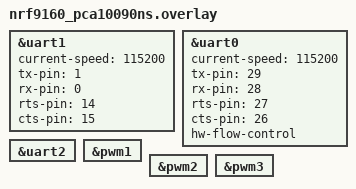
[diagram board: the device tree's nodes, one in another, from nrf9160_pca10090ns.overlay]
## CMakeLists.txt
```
#
# Copyright (c) 2018 Nordic Semiconductor ASA
#
# SPDX-License-Identifier: LicenseRef-Nordic-5-Clause
#

cmake_minimum_required(VERSION 3.20.1)

find_package(Zephyr REQUIRED HINTS $ENV{ZEPHYR_BASE})
project(aqs-gateway)

# NORDIC SDK APP START
target_sources(app PRIVATE src/main.c)
# NORDIC SDK APP END
```

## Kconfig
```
#
# Copyright (c) 2020 Nordic Semiconductor ASA
#
# SPDX-License-Identifier: LicenseRef-Nordic-5-Clause
#

menu "MQTT simple sample"
config MQTT_PUB_TOPIC
	string "MQTT publish topic"
	default "/my/publish/topic"

config MQTT_SUB_TOPIC
	string "MQTT subscribe topic"
	default "/my/subscribe/topic"

config MQTT_CLIENT_ID
	string "MQTT Client ID"
	help
	  Use a custom Client ID string. If not set, the client ID will be
	  generated based on IMEI number (for nRF9160 based targets) or
	  randomly (for other platforms).
	default ""

config MQTT_BROKER_HOSTNAME
	string "MQTT broker hostname"
	default "mqtt.eclipse.org"

config MQTT_BROKER_PORT
	int "MQTT broker port"
	default 1883

config MQTT_MESSAGE_BUFFER_SIZE
	int "MQTT message buffer size"
	default 512

config MQTT_PAYLOAD_BUFFER_SIZE
	int "MQTT payload buffer size"
	default 512

config BUTTON_EVENT_PUBLISH_MSG
	string "The message to publish on a button event"
	default "Hello from nRF91 MQTT Simple Sample"

config BUTTON_EVENT_BTN_NUM
	int "The button number"
	default 1

config MQTT_RECONNECT_DELAY_S
	int "Seconds to delay before attempting to reconnect to the broker."
	default 60

config LTE_CONNECT_RETRY_DELAY_S
	int "Seconds to delay before attempting to retry LTE connection."
	default 120

config MQTT_TLS_SEC_TAG
	int "TLS credentials security tag"
	default 24
	# default 100 (from custom version)

config MQTT_TLS_SESSION_CACHING
	bool "Enable TLS session caching"

config MQTT_TLS_PEER_VERIFY
	int "Set peer verification level"
	default 2
	# default 1 (from custom version)
	help
		Set to 0 for VERIFY_NONE, 1 for VERIFY_OPTIONAL, and 2 for
		VERIFY_REQUIRED.

endmenu

menu "Zephyr Kernel"
source "Kconfig.zephyr"
endmenu

module = MQTT_SIMPLE
module-str = MQTT Simple
source "${ZEPHYR_BASE}/subsys/logging/Kconfig.template.log_config"
```

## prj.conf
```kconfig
#
# Copyright (c) 2020 Nordic Semiconductor ASA
#
# SPDX-License-Identifier: LicenseRef-Nordic-5-Clause
#

# Networking
CONFIG_NETWORKING=y
CONFIG_NET_NATIVE=n
CONFIG_NET_SOCKETS_OFFLOAD=y
CONFIG_NET_SOCKETS=y
CONFIG_NET_SOCKETS_POSIX_NAMES=y

# LTE link control
CONFIG_LTE_NETWORK_USE_FALLBACK=n
CONFIG_LTE_LINK_CONTROL=y
CONFIG_LTE_AUTO_INIT_AND_CONNECT=n

# CONFIG_LTE_LOCK_BANDS=y
# CONFIG_LTE_LOCK_BAND_MASK="00010001100001001000"

# Modem library
CONFIG_NRF_MODEM_LIB=y

# AT Host
CONFIG_UART_INTERRUPT_DRIVEN=y
CONFIG_AT_HOST_LIBRARY=y

# MQTT
CONFIG_MQTT_LIB=y
CONFIG_MQTT_LIB_TLS=n
CONFIG_MQTT_CLEAN_SESSION=y

# IoT Hub Settings
CONFIG_MQTT_PUB_TOPIC="devices/aqsdevice27/messages/events/"
CONFIG_MQTT_SUB_TOPIC="devices/aqsdevice27messages/devicebound/"
CONFIG_MQTT_CLIENT_ID="aqsdevice22"

CONFIG_MQTT_BROKER_HOSTNAME="AquaHub2.azure-devices.net"
CONFIG_MQTT_BROKER_PORT=8883
CONFIG_MQTT_KEEPALIVE=900

# Application - Misc
CONFIG_REBOOT=y
CONFIG_SERIAL=y
CONFIG_GPIO=y
# CONFIG_UART_1_NRF_UARTE=y

# Button support
# CONFIG_DK_LIBRARY=y

# Enable logging
CONFIG_LOG=y
CONFIG_MQTT_SIMPLE_LOG_LEVEL_DBG=y
# CONFIG_LTE_LINK_CONTROL_LOG_LEVEL_DBG=y

# Memory
CONFIG_MAIN_STACK_SIZE=8192
CONFIG_HEAP_MEM_POOL_SIZE=4096
# CONFIG_SYSTEM_WORKQUEUE_STACK_SIZE=1024

# NewLib C
CONFIG_NEWLIB_LIBC=y
```

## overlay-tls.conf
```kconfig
#
# Copyright (c) 2020 Nordic Semiconductor ASA
#
# SPDX-License-Identifier: LicenseRef-Nordic-5-Clause
#

# MQTT TLS
CONFIG_MQTT_LIB_TLS=y
CONFIG_MQTT_BROKER_PORT=8883

# Application - TLS
CONFIG_MQTT_TLS_SEC_TAG=100
CONFIG_MQTT_TLS_PEER_VERIFY=1

# Modem key management, for provisioning certificates
CONFIG_MODEM_KEY_MGMT=y
```

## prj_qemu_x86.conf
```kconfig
#
# Copyright (c) 2019 Nordic Semiconductor ASA
#
# SPDX-License-Identifier: LicenseRef-BSD-5-Clause-Nordic
#
# General config
CONFIG_TEST_RANDOM_GENERATOR=y
CONFIG_NEWLIB_LIBC=y

# MQTT
CONFIG_MQTT_LIB=y
CONFIG_MQTT_LIB_TLS=y

# Networking config
CONFIG_NETWORKING=y
CONFIG_NET_IPV4=y
CONFIG_NET_TCP=y
CONFIG_NET_SOCKETS=y
CONFIG_NET_SOCKETS_POSIX_NAMES=y

CONFIG_DNS_RESOLVER=y
CONFIG_DNS_SERVER_IP_ADDRESSES=y
CONFIG_DNS_SERVER1="8.8.8.8"

# Network address config
CONFIG_NET_CONFIG_SETTINGS=y
CONFIG_NET_CONFIG_NEED_IPV4=y
CONFIG_NET_CONFIG_MY_IPV4_ADDR="192.0.2.1"
CONFIG_NET_CONFIG_PEER_IPV4_ADDR="192.0.2.2"
CONFIG_NET_CONFIG_MY_IPV4_GW="192.0.2.2"

# Appliaction
#CONFIG_MQTT_PUB_TOPIC="/my/publish/topic"
#CONFIG_MQTT_SUB_TOPIC="/my/subscribe/topic"
#CONFIG_MQTT_CLIENT_ID="my-client-id"
#CONFIG_MQTT_BROKER_HOSTNAME="mqtt.eclipse.org"
#CONFIG_MQTT_BROKER_PORT=1883

# Main thread
CONFIG_HEAP_MEM_POOL_SIZE=16384
CONFIG_MAIN_STACK_SIZE=16384
```

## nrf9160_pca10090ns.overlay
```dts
/* Needed to get NRF_UARTE2 and NRF_PWMn defined. */
//For BLG840,PCA10090,SE9160-210
&uart1 {
  current-speed = <115200>;
  status = "ok";
  tx-pin = <1>;
  rx-pin = <0>;
  rts-pin = <14>;
  cts-pin = <15>;
};

&uart0 {
  current-speed = <115200>;
  status = "ok";
  tx-pin = <29>;
  rx-pin = <28>;
  rts-pin = <27>;
  cts-pin = <26>;
  hw-flow-control;
};
//For BLE60E40F
/*
&uart0 {
  current-speed = <115200>;
  status = "ok";
  tx-pin = <1>;
  rx-pin = <0>;
  rts-pin = <14>;
  cts-pin = <15>;
};

&uart1 {
  current-speed = <115200>;
  status = "ok";
  tx-pin = <29>;
  rx-pin = <28>;
  rts-pin = <27>;
  cts-pin = <26>;
};
*/
&uart2 {
	status = "ok";
};

&pwm1 {
	status = "ok";
};

&pwm2 {
	status = "ok";
};

&pwm3 {
	status = "ok";
};
```

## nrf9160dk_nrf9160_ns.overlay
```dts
//For BLG840F
&uart0 {
  current-speed = <115200>;
  status = "ok";
  tx-pin = <29>;
  rx-pin = <28>;
  rts-pin = <27>;
  cts-pin = <26>;
  hw-flow-control; // disable if debugging on the 9160 DK
};

&pwm1 {
	status = "ok";
};

&pwm2 {
	status = "ok";
};

&pwm3 {
	status = "ok";
};
```

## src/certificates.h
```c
/*
 * Copyright (c) 2020 Nordic Semiconductor ASA
 *
 * SPDX-License-Identifier: LicenseRef-Nordic-5-Clause
 */

// Copyright (c) Microsoft. All rights reserved.
// Licensed under the MIT license. See LICENSE file in the project root for full license information.

/* This file contains certs needed to communicate with Azure (IoT) */

//#include "certs.h"
/* Note: for devices with limited resources, only one cert should be loaded. 
   #defines are used to reduce memory footprint of certificates.
   For DE and CN regions, please build with -DUSE_MICROSOFTAZURE_DE_CERT or -DUSE_PORTAL_AZURE_CN_CERT, respectively, 
   if you wish to load ONLY those certs.
*/
// #if !defined(USE_BALTIMORE_CERT) && !defined(USE_MICROSOFTAZURE_DE_CERT) && !defined(USE_PORTAL_AZURE_CN_CERT)
// // For legacy, if no certificates were explicitly selected then include all of them
// #define USE_BALTIMORE_CERT
// #define USE_MICROSOFTAZURE_DE_CERT 
// #define USE_PORTAL_AZURE_CN_CERT
// #endif
//#ifndef USE_BALTIMORE_CERT  
//#define USE_BALTIMORE_CERT
//#endif

//const char certificates[] =
///* DigiCert Baltimore Root --Used Globally--*/
//// This cert should be used when connecting to Azure IoT on the Azure Cloud available globally. When in doubt, use this cert.
//"-----BEGIN CERTIFICATE-----MIIDdzCCAl+gAwIBAgIEAgAAuTANBgkqhkiG9w0BAQUFADBaMQswCQYDVQQGEwJJRTESMBAGA1UEChMJQmFsdGltb3JlMRMwEQYDVQQLEwpDeWJlclRydXN0MSIwIAYDVQQDExlCYWx0aW1vcmUgQ3liZXJUcnVzdCBSb290MB4XDTAwMDUxMjE4NDYwMFoXDTI1MDUxMjIzNTkwMFowWjELMAkGA1UEBhMCSUUxEjAQBgNVBAoTCUJhbHRpbW9yZTETMBEGA1UECxMKQ3liZXJUcnVzdDEiMCAGA1UEAxMZQmFsdGltb3JlIEN5YmVyVHJ1c3QgUm9vdDCCASIwDQYJKoZIhvcNAQEBBQADggEPADCCAQoCggEBAKMEuyKrmD1X6CZymrV51Cni4eiVgLGw41uOKymaZN+hXe2wCQVt2yguzmKiYv60iNoS6zjrIZ3AQSsBUnuId9Mcj8e6uYi1agnnc+gRQKfRzMpijS3ljwumUNKoUMMo6vWrJYeKmpYcqWe4PwzV9/lSEy/CG9VwcPCPwBLKBsua4dnKM3p31vjsufFoREJIE9LAwqSuXmD+tqYF/LTdB1kC1FkYmGP1pWPgkAx9XbIGevOF6uvUA65ehD5f/xXtabz5OTZydc93Uk3zyZAsuT3lySNTPx8kmCFcB5kpvcY67Oduhjprl3RjM71oGDHweI12v/yejl0qhqdNkNwnGjkCAwEAAaNFMEMwHQYDVR0OBBYEFOWdWTCCR1jMrPoIVDaGezq1BE3wMBIGA1UdEwEB/wQIMAYBAf8CAQMwDgYDVR0PAQH/BAQDAgEGMA0GCSqGSIb3DQEBBQUAA4IBAQCFDF2O5G9RaEIFoN27TyclhAO992T9Ldcw46QQF+vaKSm2eT929hkTI7gQCvlYpNRhcL0EYWoSihfVCr3FvDB81ukMJY2GQE/szKN+OMY3EU/t3WgxjkzSswF07r51XgdIGn9w/xZchMB5hbgF/X++ZRGjD8ACtPhSNzkE1akxehi/oCr0Epn3o0WC4zxe9Z2etciefC7IpJ5OCBRLbf1wbWsaY71k5h+3zvDyny67G7fyUIhzksLi4xaNmjICq44Y3ekQEe5+NauQrz4wlHrQMz2nZQ/1/I6eYs9HRCwBXbsdtTLSR9I4LtD+gdwyah617jzV/OeBHRnDJELqYzmp-----END CERTIFICATE-----"
//;

#define CA_CERTIFICATE \
	"-----BEGIN CERTIFICATE-----\n" \
	"MIIDdzCCAl+gAwIBAgIEAgAAuTANBgkqhkiG9w0BAQUFADBaMQswCQYDVQQGEwJJ\n" \
	"RTESMBAGA1UEChMJQmFsdGltb3JlMRMwEQYDVQQLEwpDeWJlclRydXN0MSIwIAYD\n" \
	"VQQDExlCYWx0aW1vcmUgQ3liZXJUcnVzdCBSb290MB4XDTAwMDUxMjE4NDYwMFoX\n" \
	"DTI1MDUxMjIzNTkwMFowWjELMAkGA1UEBhMCSUUxEjAQBgNVBAoTCUJhbHRpbW9y\n" \
	"ZTETMBEGA1UECxMKQ3liZXJUcnVzdDEiMCAGA1UEAxMZQmFsdGltb3JlIEN5YmVy\n" \
	"VHJ1c3QgUm9vdDCCASIwDQYJKoZIhvcNAQEBBQADggEPADCCAQoCggEBAKMEuyKr\n" \
	"mD1X6CZymrV51Cni4eiVgLGw41uOKymaZN+hXe2wCQVt2yguzmKiYv60iNoS6zjr\n" \
	"IZ3AQSsBUnuId9Mcj8e6uYi1agnnc+gRQKfRzMpijS3ljwumUNKoUMMo6vWrJYeK\n" \
	"mpYcqWe4PwzV9/lSEy/CG9VwcPCPwBLKBsua4dnKM3p31vjsufFoREJIE9LAwqSu\n" \
	"XmD+tqYF/LTdB1kC1FkYmGP1pWPgkAx9XbIGevOF6uvUA65ehD5f/xXtabz5OTZy\n" \
	"dc93Uk3zyZAsuT3lySNTPx8kmCFcB5kpvcY67Oduhjprl3RjM71oGDHweI12v/ye\n" \
	"jl0qhqdNkNwnGjkCAwEAAaNFMEMwHQYDVR0OBBYEFOWdWTCCR1jMrPoIVDaGezq1\n" \
	"BE3wMBIGA1UdEwEB/wQIMAYBAf8CAQMwDgYDVR0PAQH/BAQDAgEGMA0GCSqGSIb3\n" \
	"DQEBBQUAA4IBAQCFDF2O5G9RaEIFoN27TyclhAO992T9Ldcw46QQF+vaKSm2eT92\n" \
	"9hkTI7gQCvlYpNRhcL0EYWoSihfVCr3FvDB81ukMJY2GQE/szKN+OMY3EU/t3Wgx\n" \
	"jkzSswF07r51XgdIGn9w/xZchMB5hbgF/X++ZRGjD8ACtPhSNzkE1akxehi/oCr0\n" \
	"Epn3o0WC4zxe9Z2etciefC7IpJ5OCBRLbf1wbWsaY71k5h+3zvDyny67G7fyUIhz\n" \
	"ksLi4xaNmjICq44Y3ekQEe5+NauQrz4wlHrQMz2nZQ/1/I6eYs9HRCwBXbsdtTLS\n" \
	"R9I4LtD+gdwyah617jzV/OeBHRnDJELqYzmp\n" \
	"-----END CERTIFICATE-----\n"
```

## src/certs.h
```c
// Copyright (c) Microsoft. All rights reserved.
// Licensed under the MIT license. See LICENSE file in the project root for full license information.

/* This file contains certs needed to communicate with Azure (IoT) */

//#include "certs.h"
/* Note: for devices with limited resources, only one cert should be loaded. 
   #defines are used to reduce memory footprint of certificates.
   For DE and CN regions, please build with -DUSE_MICROSOFTAZURE_DE_CERT or -DUSE_PORTAL_AZURE_CN_CERT, respectively, 
   if you wish to load ONLY those certs.
*/
// #if !defined(USE_BALTIMORE_CERT) && !defined(USE_MICROSOFTAZURE_DE_CERT) && !defined(USE_PORTAL_AZURE_CN_CERT)
// // For legacy, if no certificates were explicitly selected then include all of them
// #define USE_BALTIMORE_CERT
// #define USE_MICROSOFTAZURE_DE_CERT 
// #define USE_PORTAL_AZURE_CN_CERT
// #endif
//#ifndef USE_BALTIMORE_CERT  
//#define USE_BALTIMORE_CERT
//#endif

//const char certificates[] =
///* DigiCert Baltimore Root --Used Globally--*/
//// This cert should be used when connecting to Azure IoT on the Azure Cloud available globally. When in doubt, use this cert.
//"-----BEGIN CERTIFICATE-----MIIDdzCCAl+gAwIBAgIEAgAAuTANBgkqhkiG9w0BAQUFADBaMQswCQYDVQQGEwJJRTESMBAGA1UEChMJQmFsdGltb3JlMRMwEQYDVQQLEwpDeWJlclRydXN0MSIwIAYDVQQDExlCYWx0aW1vcmUgQ3liZXJUcnVzdCBSb290MB4XDTAwMDUxMjE4NDYwMFoXDTI1MDUxMjIzNTkwMFowWjELMAkGA1UEBhMCSUUxEjAQBgNVBAoTCUJhbHRpbW9yZTETMBEGA1UECxMKQ3liZXJUcnVzdDEiMCAGA1UEAxMZQmFsdGltb3JlIEN5YmVyVHJ1c3QgUm9vdDCCASIwDQYJKoZIhvcNAQEBBQADggEPADCCAQoCggEBAKMEuyKrmD1X6CZymrV51Cni4eiVgLGw41uOKymaZN+hXe2wCQVt2yguzmKiYv60iNoS6zjrIZ3AQSsBUnuId9Mcj8e6uYi1agnnc+gRQKfRzMpijS3ljwumUNKoUMMo6vWrJYeKmpYcqWe4PwzV9/lSEy/CG9VwcPCPwBLKBsua4dnKM3p31vjsufFoREJIE9LAwqSuXmD+tqYF/LTdB1kC1FkYmGP1pWPgkAx9XbIGevOF6uvUA65ehD5f/xXtabz5OTZydc93Uk3zyZAsuT3lySNTPx8kmCFcB5kpvcY67Oduhjprl3RjM71oGDHweI12v/yejl0qhqdNkNwnGjkCAwEAAaNFMEMwHQYDVR0OBBYEFOWdWTCCR1jMrPoIVDaGezq1BE3wMBIGA1UdEwEB/wQIMAYBAf8CAQMwDgYDVR0PAQH/BAQDAgEGMA0GCSqGSIb3DQEBBQUAA4IBAQCFDF2O5G9RaEIFoN27TyclhAO992T9Ldcw46QQF+vaKSm2eT929hkTI7gQCvlYpNRhcL0EYWoSihfVCr3FvDB81ukMJY2GQE/szKN+OMY3EU/t3WgxjkzSswF07r51XgdIGn9w/xZchMB5hbgF/X++ZRGjD8ACtPhSNzkE1akxehi/oCr0Epn3o0WC4zxe9Z2etciefC7IpJ5OCBRLbf1wbWsaY71k5h+3zvDyny67G7fyUIhzksLi4xaNmjICq44Y3ekQEe5+NauQrz4wlHrQMz2nZQ/1/I6eYs9HRCwBXbsdtTLSR9I4LtD+gdwyah617jzV/OeBHRnDJELqYzmp-----END CERTIFICATE-----"
//;


const char* certificates = {
"-----BEGIN CERTIFICATE-----\r\n"
"MIIDdzCCAl+gAwIBAgIEAgAAuTANBgkqhkiG9w0BAQUFADBaMQswCQYDVQQGEwJJ\r\n"
"RTESMBAGA1UEChMJQmFsdGltb3JlMRMwEQYDVQQLEwpDeWJlclRydXN0MSIwIAYD\r\n"
"VQQDExlCYWx0aW1vcmUgQ3liZXJUcnVzdCBSb290MB4XDTAwMDUxMjE4NDYwMFoX\r\n"
"DTI1MDUxMjIzNTkwMFowWjELMAkGA1UEBhMCSUUxEjAQBgNVBAoTCUJhbHRpbW9y\r\n"
"ZTETMBEGA1UECxMKQ3liZXJUcnVzdDEiMCAGA1UEAxMZQmFsdGltb3JlIEN5YmVy\r\n"
"VHJ1c3QgUm9vdDCCASIwDQYJKoZIhvcNAQEBBQADggEPADCCAQoCggEBAKMEuyKr\r\n"
"mD1X6CZymrV51Cni4eiVgLGw41uOKymaZN+hXe2wCQVt2yguzmKiYv60iNoS6zjr\r\n"
"IZ3AQSsBUnuId9Mcj8e6uYi1agnnc+gRQKfRzMpijS3ljwumUNKoUMMo6vWrJYeK\r\n"
"mpYcqWe4PwzV9/lSEy/CG9VwcPCPwBLKBsua4dnKM3p31vjsufFoREJIE9LAwqSu\r\n"
"XmD+tqYF/LTdB1kC1FkYmGP1pWPgkAx9XbIGevOF6uvUA65ehD5f/xXtabz5OTZy\r\n"
"dc93Uk3zyZAsuT3lySNTPx8kmCFcB5kpvcY67Oduhjprl3RjM71oGDHweI12v/ye\r\n"
"jl0qhqdNkNwnGjkCAwEAAaNFMEMwHQYDVR0OBBYEFOWdWTCCR1jMrPoIVDaGezq1\r\n"
"BE3wMBIGA1UdEwEB/wQIMAYBAf8CAQMwDgYDVR0PAQH/BAQDAgEGMA0GCSqGSIb3\r\n"
"DQEBBQUAA4IBAQCFDF2O5G9RaEIFoN27TyclhAO992T9Ldcw46QQF+vaKSm2eT92\r\n"
"9hkTI7gQCvlYpNRhcL0EYWoSihfVCr3FvDB81ukMJY2GQE/szKN+OMY3EU/t3Wgx\r\n"
"jkzSswF07r51XgdIGn9w/xZchMB5hbgF/X++ZRGjD8ACtPhSNzkE1akxehi/oCr0\r\n"
"Epn3o0WC4zxe9Z2etciefC7IpJ5OCBRLbf1wbWsaY71k5h+3zvDyny67G7fyUIhz\r\n"
"ksLi4xaNmjICq44Y3ekQEe5+NauQrz4wlHrQMz2nZQ/1/I6eYs9HRCwBXbsdtTLS\r\n"
"R9I4LtD+gdwyah617jzV/OeBHRnDJELqYzmp\r\n"
"-----END CERTIFICATE-----\r\n"
};


//#define certificates "-----BEGIN CERTIFICATE-----"\
//"MIIDdzCCAl+gAwIBAgIEAgAAuTANBgkqhkiG9w0BAQUFADBaMQswCQYDVQQGEwJJ"\
//"RTESMBAGA1UEChMJQmFsdGltb3JlMRMwEQYDVQQLEwpDeWJlclRydXN0MSIwIAYD"\
//"VQQDExlCYWx0aW1vcmUgQ3liZXJUcnVzdCBSb290MB4XDTAwMDUxMjE4NDYwMFoX"\
//"DTI1MDUxMjIzNTkwMFowWjELMAkGA1UEBhMCSUUxEjAQBgNVBAoTCUJhbHRpbW9y"\
//"ZTETMBEGA1UECxMKQ3liZXJUcnVzdDEiMCAGA1UEAxMZQmFsdGltb3JlIEN5YmVy"\
//"VHJ1c3QgUm9vdDCCASIwDQYJKoZIhvcNAQEBBQADggEPADCCAQoCggEBAKMEuyKr"\
//"mD1X6CZymrV51Cni4eiVgLGw41uOKymaZN+hXe2wCQVt2yguzmKiYv60iNoS6zjr"\
//"IZ3AQSsBUnuId9Mcj8e6uYi1agnnc+gRQKfRzMpijS3ljwumUNKoUMMo6vWrJYeK"\
//"mpYcqWe4PwzV9/lSEy/CG9VwcPCPwBLKBsua4dnKM3p31vjsufFoREJIE9LAwqSu"\
//"XmD+tqYF/LTdB1kC1FkYmGP1pWPgkAx9XbIGevOF6uvUA65ehD5f/xXtabz5OTZy"\
//"dc93Uk3zyZAsuT3lySNTPx8kmCFcB5kpvcY67Oduhjprl3RjM71oGDHweI12v/ye"\
//"jl0qhqdNkNwnGjkCAwEAAaNFMEMwHQYDVR0OBBYEFOWdWTCCR1jMrPoIVDaGezq1"\
//"BE3wMBIGA1UdEwEB/wQIMAYBAf8CAQMwDgYDVR0PAQH/BAQDAgEGMA0GCSqGSIb3"\
//"DQEBBQUAA4IBAQCFDF2O5G9RaEIFoN27TyclhAO992T9Ldcw46QQF+vaKSm2eT92"\
//"9hkTI7gQCvlYpNRhcL0EYWoSihfVCr3FvDB81ukMJY2GQE/szKN+OMY3EU/t3Wgx"\
//"jkzSswF07r51XgdIGn9w/xZchMB5hbgF/X++ZRGjD8ACtPhSNzkE1akxehi/oCr0"\
//"Epn3o0WC4zxe9Z2etciefC7IpJ5OCBRLbf1wbWsaY71k5h+3zvDyny67G7fyUIhz"\
//"ksLi4xaNmjICq44Y3ekQEe5+NauQrz4wlHrQMz2nZQ/1/I6eYs9HRCwBXbsdtTLS"\
//"R9I4LtD+gdwyah617jzV/OeBHRnDJELqYzmp"\
//"-----END CERTIFICATE-----"
```

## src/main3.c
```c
/*
 * Copyright (c) 2018 Nordic Semiconductor ASA
 *
 * SPDX-License-Identifier: LicenseRef-BSD-5-Clause-Nordic
 */

#include <zephyr.h>
#include <stdio.h>
#include <drivers/uart.h>
#include <string.h>

#include <net/mqtt.h>
#include <net/socket.h>
#include <lte_lc.h>
#if defined(CONFIG_LWM2M_CARRIER)
#include <lwm2m_carrier.h>
#endif

#include "certs.h"
#include <modem_key_mgmt.h>
#include <at_cmd.h> // todo: probably don't need this

static const char* CONFIG_MQTT_BROKER_PASSWORD = "SharedAccessSignature sr=Aquahub.azure-devices.net%2Fdevices%2Faquadevice&sig=MjnaRLJFb5UxsQu8PCQtrP8UUIyQbncREHFL%2BvlkCHw%3D&se=1614554527";
static const char* CONFIG_MQTT_BROKER_USERNAME = "Aquahub.azure-devices.net/aquadevice/?api-version=2018-06-30";

#if defined(CONFIG_MQTT_LIB_TLS)
static sec_tag_t sec_tag_list[] = { CONFIG_SEC_TAG };
#endif /* defined(CONFIG_MQTT_LIB_TLS) */ 

/* Buffers for MQTT client. */
static u8_t rx_buffer[CONFIG_MQTT_MESSAGE_BUFFER_SIZE];
static u8_t tx_buffer[CONFIG_MQTT_MESSAGE_BUFFER_SIZE];
static u8_t payload_buf[CONFIG_MQTT_PAYLOAD_BUFFER_SIZE];

/* The mqtt client struct */
static struct mqtt_client client;

/* MQTT Broker details. */
static struct sockaddr_storage broker;

/* Connected flag */
static bool connected;

/* File descriptor */
static struct pollfd fds;

#if defined(CONFIG_BSD_LIBRARY)

/* UART variables */
#define UART_BUF_SIZE           128
static struct device  *dev_uart;
static K_FIFO_DEFINE(fifo_uart_tx_data);
static K_FIFO_DEFINE(fifo_uart_rx_data);
static u8_t uart_rxbuf[UART_BUF_SIZE];
static u8_t uart_rx_leng=0;
struct uart_data_t {
	void  *fifo_reserved;
	u8_t    data[UART_BUF_SIZE];
	u16_t   len;
};
uint8_t data_uart[UART_BUF_SIZE];
volatile bool vChanged = false;

volatile uint16_t nRun = 0;
uint32_t numPublished = 0;
static void sendCloudMsg(void);

// Timer stuff
#define TIMER_INTERVAL_MSEC 500
struct k_timer timer_msg_send;

// Workqueue stuff
#define MY_STACK_SIZE 512
#define MY_PRIORITY 5
K_THREAD_STACK_DEFINE(my_stack_area, MY_STACK_SIZE);
struct k_work_q queue_work_msg_send;
void work_handler_msg_send(struct k_work *work);
K_WORK_DEFINE(my_work, work_handler_msg_send);
void timer_handler_msg_send(struct k_timer *timer_id);

/**@brief Recoverable BSD library error. */
void bsd_recoverable_error_handler(uint32_t err)
{
	printk("bsdlib recoverable error: %u\n", (unsigned int)err);
}

#endif /* defined(CONFIG_BSD_LIBRARY) */

#if defined(CONFIG_LWM2M_CARRIER)
K_SEM_DEFINE(carrier_registered, 0, 1);

void lwm2m_carrier_event_handler(const lwm2m_carrier_event_t *event)
{
	switch (event->type) {
	case LWM2M_CARRIER_EVENT_BSDLIB_INIT:
		printk("LWM2M_CARRIER_EVENT_BSDLIB_INIT\n");
		break;
	case LWM2M_CARRIER_EVENT_CONNECT:
		printk("LWM2M_CARRIER_EVENT_CONNECT\n");
		break;
	case LWM2M_CARRIER_EVENT_DISCONNECT:
		printk("LWM2M_CARRIER_EVENT_DISCONNECT\n");
		break;
	case LWM2M_CARRIER_EVENT_READY:
		printk("LWM2M_CARRIER_EVENT_READY\n");
		k_sem_give(&carrier_registered);
		break;
	case LWM2M_CARRIER_EVENT_FOTA_START:
		printk("LWM2M_CARRIER_EVENT_FOTA_START\n");
		break;
	case LWM2M_CARRIER_EVENT_REBOOT:
		printk("LWM2M_CARRIER_EVENT_REBOOT\n");
		break;
	}
}
#endif /* defined(CONFIG_LWM2M_CARRIER) */

/**@brief Function to print strings without null-termination
 */
static void data_print(u8_t *prefix, u8_t *data, size_t len)
{
	char buf[len + 1];

	memcpy(buf, data, len);
	buf[len] = 0;
	printk("%s%s\n", prefix, buf);
}

/**@brief Function to publish data on the configured topic
 */
static int data_publish(struct mqtt_client *c, enum mqtt_qos qos,
	u8_t *data, size_t len)
{
	struct mqtt_publish_param param;

	param.message.topic.qos = qos;
	param.message.topic.topic.utf8 = CONFIG_MQTT_PUB_TOPIC;
	param.message.topic.topic.size = strlen(CONFIG_MQTT_PUB_TOPIC);
	param.message.payload.data = data;
	param.message.payload.len = len;
	param.message_id = sys_rand32_get();
	param.dup_flag = 0;
	param.retain_flag = 0;

//	data_print("Publishing: ", data, len);
//	printk("to topic: %s len: %u\n",
//		CONFIG_MQTT_PUB_TOPIC,
//		(unsigned int)strlen(CONFIG_MQTT_PUB_TOPIC));

	return mqtt_publish(c, &param);
}

/**@brief Function to subscribe to the configured topic
 */
static int subscribe(void)
{
	struct mqtt_topic subscribe_topic = {
		.topic = {
			.utf8 = CONFIG_MQTT_SUB_TOPIC,
			.size = strlen(CONFIG_MQTT_SUB_TOPIC)
		},
		.qos = MQTT_QOS_1_AT_LEAST_ONCE
	};

	const struct mqtt_subscription_list subscription_list = {
		.list = &subscribe_topic,
		.list_count = 1,
		.message_id = 1234
	};

//	printk("Subscribing to: %s len %u\n", CONFIG_MQTT_SUB_TOPIC,
//		(unsigned int)strlen(CONFIG_MQTT_SUB_TOPIC));

	return mqtt_subscribe(&client, &subscription_list);
}

/**@brief Function to read the published payload.
 */
static int publish_get_payload(struct mqtt_client *c, size_t length)
{
	u8_t *buf = payload_buf;
	u8_t *end = buf + length;

	if (length > sizeof(payload_buf)) {
		return -EMSGSIZE;
	}

	while (buf < end) {
		int ret = mqtt_read_publish_payload(c, buf, end - buf);

		if (ret < 0) {
			int err;

			if (ret != -EAGAIN) {
				return ret;
			}

			printk("mqtt_read_publish_payload: EAGAIN\n");

			err = poll(&fds, 1, K_SECONDS(CONFIG_MQTT_KEEPALIVE));
			if (err > 0 && (fds.revents & POLLIN) == POLLIN) {
				continue;
			} else {
				return -EIO;
			}
		}

		if (ret == 0) {
			return -EIO;
		}

		buf += ret;
	}

	return 0;
}

/**@brief MQTT client event handler
 */
void mqtt_evt_handler(struct mqtt_client *const c,
		      const struct mqtt_evt *evt)
{
	int err;

	switch (evt->type) {
	case MQTT_EVT_CONNACK:
		if (evt->result != 0) {
			printk("MQTT connect failed %d\n", evt->result);
			break;
		}

		connected = true;
		//printk("[%s:%d] MQTT client connected!\n", __func__, __LINE__);
		subscribe();
		break;

	case MQTT_EVT_DISCONNECT:
		printk("[%s:%d] MQTT client disconnected %d\n", __func__,
		       __LINE__, evt->result);

		connected = false;
		break;

	case MQTT_EVT_PUBLISH: {
		const struct mqtt_publish_param *p = &evt->param.publish;

//		printk("[%s:%d] MQTT PUBLISH result=%d len=%d\n", __func__,
//		       __LINE__, evt->result, p->message.payload.len);
		err = publish_get_payload(c, p->message.payload.len);
		if (err >= 0) {
//			data_print("Received: ", payload_buf,
//				p->message.payload.len);
			/* Echo back received data */
			data_publish(&client, MQTT_QOS_1_AT_LEAST_ONCE,
				payload_buf, p->message.payload.len);
		} else {
			printk("mqtt_read_publish_payload: Failed! %d\n", err);
			printk("Disconnecting MQTT client...\n");

			err = mqtt_disconnect(c);
			if (err) {
				printk("Could not disconnect: %d\n", err);
			}
		}
	} break;

	case MQTT_EVT_PUBACK:
		if (evt->result != 0) {
			printk("MQTT PUBACK error %d\n", evt->result);
			break;
		}

		printk("[%s:%d] PUBACK packet id: %u\n", __func__, __LINE__,
				evt->param.puback.message_id);
                nRun = 0;
                numPublished++;
                //printk("Messages published this session: %i\n", numPublished);
		break;

	case MQTT_EVT_SUBACK:
		if (evt->result != 0) {
			printk("MQTT SUBACK error %d\n", evt->result);
			break;
		}

		printk("[%s:%d] SUBACK packet id: %u\n", __func__, __LINE__,
				evt->param.suback.message_id);
		break;

	default:
		printk("[%s:%d] default: %d\n", __func__, __LINE__,
				evt->type);
		break;
	}
}

/**@brief Resolves the configured hostname and
 * initializes the MQTT broker structure
 */
static void broker_init(void)
{
	int err;
	struct addrinfo *result;
	struct addrinfo *addr;
	struct addrinfo hints = {
		.ai_family = AF_INET,
		.ai_socktype = SOCK_STREAM
	};

	err = getaddrinfo(CONFIG_MQTT_BROKER_HOSTNAME, NULL, &hints, &result);
	if (err) {
		printk("ERROR: getaddrinfo failed %d\n", err);

		return;
	}

	addr = result;
	err = -ENOENT;

	/* Look for address of the broker. */
	while (addr != NULL) {
		/* IPv4 Address. */
		if (addr->ai_addrlen == sizeof(struct sockaddr_in)) {
			struct sockaddr_in *broker4 =
				((struct sockaddr_in *)&broker);
			char ipv4_addr[NET_IPV4_ADDR_LEN];

			broker4->sin_addr.s_addr =
				((struct sockaddr_in *)addr->ai_addr)
				->sin_addr.s_addr;
			broker4->sin_family = AF_INET;
			broker4->sin_port = htons(CONFIG_MQTT_BROKER_PORT);

			inet_ntop(AF_INET, &broker4->sin_addr.s_addr,
				  ipv4_addr, sizeof(ipv4_addr));
			//printk("IPv4 Address found %s\n", ipv4_addr);

			break;
		} else {
//			printk("ai_addrlen = %u should be %u or %u\n",
//				(unsigned int)addr->ai_addrlen,
//				(unsigned int)sizeof(struct sockaddr_in),
//				(unsigned int)sizeof(struct sockaddr_in6));
		}

		addr = addr->ai_next;
		break;
	}

	/* Free the address. */
	freeaddrinfo(result);
}

/**@brief Initialize the MQTT client structure
 */
static void client_init(struct mqtt_client *client)
{
        //printk("mqtt_client_init(client)\r\n");
	mqtt_client_init(client);

        //printk("broker_init()\r\n");
	broker_init();
        //printk("broker_init() finished\r\n");

        /* MQTT client configuration */
        static struct mqtt_utf8 password;
	static struct mqtt_utf8 user_name;

	password.utf8 = (u8_t*)CONFIG_MQTT_BROKER_PASSWORD;
	password.size = strlen(CONFIG_MQTT_BROKER_PASSWORD);
	user_name.utf8 = (u8_t*)CONFIG_MQTT_BROKER_USERNAME;
	user_name.size = strlen(CONFIG_MQTT_BROKER_USERNAME);

	client->broker = &broker;
	client->evt_cb = mqtt_evt_handler;
	client->client_id.utf8 = (u8_t *)CONFIG_MQTT_CLIENT_ID;
	client->client_id.size = strlen(CONFIG_MQTT_CLIENT_ID);
	client->password = &password;
	client->user_name = &user_name;
	client->protocol_version = MQTT_VERSION_3_1_1;

	/* MQTT buffers configuration */
	client->rx_buf = rx_buffer;
	client->rx_buf_size = sizeof(rx_buffer);
	client->tx_buf = tx_buffer;
	client->tx_buf_size = sizeof(tx_buffer);

#if defined(CONFIG_MQTT_LIB_TLS)
    struct mqtt_sec_config *tls_config = &client->transport.tls.config;
    
    client->transport.type = MQTT_TRANSPORT_SECURE;
    
    //tls_config->peer_verify = CONFIG_PEER_VERIFY;
    tls_config->peer_verify = 1;
    tls_config->cipher_count = 0;
    tls_config->cipher_list = NULL;
    tls_config->sec_tag_count = ARRAY_SIZE(sec_tag_list);
    tls_config->sec_tag_list = sec_tag_list;
    tls_config->hostname = CONFIG_MQTT_BROKER_HOSTNAME;
#else /* MQTT transport configuration */
    client->transport.type = MQTT_TRANSPORT_NON_SECURE;
#endif /* defined(CONFIG_MQTT_LIB_TLS) */
}

/**@brief Initialize the file descriptor structure used by poll.
 */
static int fds_init(struct mqtt_client *c)
{
	if (c->transport.type == MQTT_TRANSPORT_NON_SECURE) {
		fds.fd = c->transport.tcp.sock;
	} else {
#if defined(CONFIG_MQTT_LIB_TLS)
		fds.fd = c->transport.tls.sock;
#else
		return -ENOTSUP;
#endif
	}

	fds.events = POLLIN;

	return 0;
}

/**@brief Configures modem to provide LTE link. Blocks until link is
 * successfully established.
 */
static void modem_configure(void)
{
#if defined(CONFIG_LTE_LINK_CONTROL)
	if (IS_ENABLED(CONFIG_LTE_AUTO_INIT_AND_CONNECT)) {
		/* Do nothing, modem is already turned on
		 * and connected.
		 */
	} else {
#if defined(CONFIG_LWM2M_CARRIER)
		/* Wait for the LWM2M_CARRIER to configure the modem and
		 * start the connection.
		 */
		printk("Waitng for carrier registration...\n");
		k_sem_take(&carrier_registered, K_FOREVER);
		printk("Registered!\n");
#else /* defined(CONFIG_LWM2M_CARRIER) */
		int err;

		//printk("LTE Link Connecting ...\n");
		err = lte_lc_init_and_connect();
		__ASSERT(err == 0, "LTE link could not be established.");
		//printk("LTE Link Connected!\n");
#endif /* defined(CONFIG_LWM2M_CARRIER) */
	}
#endif /* defined(CONFIG_LTE_LINK_CONTROL) */
}

static void certificate_init(void) // todo - probably shouldn't rewrite the credentials EVERY time (at least, not every time an mqtt connection fails
{
  int err;
  enum lte_lc_func_mode system_mode_now;
  nrf_sec_tag_t sec_tag = (nrf_sec_tag_t) sec_tag_list[0];
  bool cred_exists = false;
  u8_t perm_flags_tmp;
  //printk("\n Add cert \n");

  // Get current system mode
  err = lte_lc_func_mode_get(&system_mode_now);
  if (err < 0) {
    printk("Error getting system mode");
  }

  // Turn modem offline if it isn't already
  if (system_mode_now != LTE_LC_FUNC_MODE_OFFLINE) {
    //printk("Modem is not offline - will make it offline\n");
    err = lte_lc_offline();
    __ASSERT(err == 0, "Could not turn modem offline.");
  }

  // Check if credential exists already - if so, delete
  err = modem_key_mgmt_exists(sec_tag, MODEM_KEY_MGMT_CRED_TYPE_CA_CHAIN, &cred_exists, &perm_flags_tmp);
  __ASSERT(err == 0, "Could not check if key exists.");
  if (cred_exists) {
    //printk("Cred exists\n");
    err = modem_key_mgmt_delete(sec_tag, MODEM_KEY_MGMT_CRED_TYPE_CA_CHAIN);
    if (err < 0) {
      printk("ERROR: key delete %d\n", errno);
    }
  }

  // Write credential
  err = modem_key_mgmt_write(sec_tag, MODEM_KEY_MGMT_CRED_TYPE_CA_CHAIN, certificates, strlen(certificates));
  //printk("strlen(certificates): %i \n", strlen(certificates));
  if (err < 0) {
    printk("ERROR: key write %d\n", err);
  }

}


static void uart_cb(struct device *uart)
{
        uint8_t temp_rx[UART_BUF_SIZE];
        int data_length=0;
	uart_irq_update(uart);
	if (uart_irq_rx_ready(uart)) {
                data_length = uart_fifo_read(uart, temp_rx, sizeof(temp_rx));
		temp_rx[data_length] = 0;
	}
        for(int i=0;i<data_length ;i++){
          uart_rxbuf[uart_rx_leng] = temp_rx[i];
          uart_rx_leng++;

        }

        if (uart_rx_leng > 0) {
          if ((uart_rx_leng == UART_BUF_SIZE) || (uart_rxbuf[uart_rx_leng - 1] == 0x0a) || (uart_rxbuf[uart_rx_leng - 2] == 0x0d)){  
            if (uart_rx_leng > 35 && uart_rx_leng < UART_BUF_SIZE) {
              //printk("C:%s\n",data_uart);
              if (vChanged == false) {
                uint8_t pos_modifier = 0;
                if (uart_rxbuf[uart_rx_leng - 1] == 0x0a) pos_modifier++;
                if (uart_rxbuf[uart_rx_leng - 2] == 0x0d) pos_modifier++;
                memset(data_uart, '\0', sizeof(data_uart));
                strncpy(data_uart, uart_rxbuf, uart_rx_leng-pos_modifier);
                vChanged = true;
              }
            }
            uart_rxbuf[0] = 0;
            uart_rx_leng = 0;     
          }
	}

       	if (uart_irq_tx_ready(uart)) {
        	struct uart_data_t *buf =
			k_fifo_get(&fifo_uart_tx_data, K_NO_WAIT);
		u16_t written = 0;
		/* Nothing in the FIFO, nothing to send */
		if (!buf) {
			uart_irq_tx_disable(uart);
			return;
		}
		while (buf->len > written) {
			written += uart_fifo_fill(uart,
						  &buf->data[written],
						  buf->len - written);
		}
		while (!uart_irq_tx_complete(uart)) {
			/* Wait for the last byte to get
			 * shifted out of the module
			 */
		}
		if (k_fifo_is_empty(&fifo_uart_tx_data)) {
			uart_irq_tx_disable(uart);
		}
		k_free(buf);
	}
}



static int init_uart(void)
{


	dev_uart = device_get_binding("UART_0");
	if (!dev_uart) {
		return -ENXIO;
	}

	uart_irq_callback_set(dev_uart, uart_cb);
	uart_irq_rx_enable(dev_uart);

	return 0;
}

static void sendCloudMsg(void)
{
  int err_dp = data_publish(&client, MQTT_QOS_1_AT_LEAST_ONCE, data_uart, strlen(data_uart));
}


void work_handler_msg_send(struct k_work *work)
{
    sendCloudMsg();
}

void timer_handler_msg_send(struct k_timer *timer_id)
{
//  printk("timer____\r\n");
  if (nRun == 0) {
    if (vChanged == true) {
      printk("___ALL TRUE \r\n");
      nRun=1;
      vChanged = false;
      k_work_submit(&queue_work_msg_send);
    }
  }
}


void main(void)
{
	int err;
	k_sleep(K_SECONDS(6));

	printk("The MQTT simple sample started\n");

        uint8_t mqtt_conn_attempts = 0;
        uint8_t mqtt_conn_max_tries = 10;
        do {
            // wait 5 seconds before attempting to reconnect
            if (mqtt_conn_attempts > 0) {
              k_sleep(K_SECONDS(5));
            }
            certificate_init();

            modem_configure();

            client_init(&client);

            err = mqtt_connect(&client);
            if (err != 0) {
                    printk("ERROR: mqtt_connect %d\n", err);
            }
            mqtt_conn_attempts++;
            //printk("MQTT_CONN_ATTEMPTS: %i\n", mqtt_conn_attempts);
        }while(err != 0 && mqtt_conn_attempts < mqtt_conn_max_tries);
        // if still not connected, end program
        if (err != 0) {
          return;
        }

	err = fds_init(&client);
	if (err != 0) {
		printk("ERROR: fds_init %d\n", err);
		return;
	}

        err = init_uart();
	if (!err) {
		//printk("UART enabled\n");
               
	}else{
		printk("UART enable error\n");
        }


        k_work_init(&queue_work_msg_send, work_handler_msg_send);



        k_timer_init(&timer_msg_send, timer_handler_msg_send, NULL);
        k_timer_start(&timer_msg_send, K_MSEC(TIMER_INTERVAL_MSEC), K_MSEC(TIMER_INTERVAL_MSEC));
       

	while (1) {
		err = poll(&fds, 1, mqtt_keepalive_time_left(&client));
		if (err < 0) {
			printk("ERROR: poll %d\n", errno); // err or errno?
			break;
		}

		err = mqtt_live(&client);
		if ((err != 0) && (err != -EAGAIN)) {
			printk("ERROR: mqtt_live %d\n", err);
			break;
		}

		if ((fds.revents & POLLIN) == POLLIN) {
			err = mqtt_input(&client);
			if (err != 0) {
				printk("ERROR: mqtt_input %d\n", err);
				break;
			}
		}

		if ((fds.revents & POLLERR) == POLLERR) {
			printk("POLLERR\n");
			break;
		}

		if ((fds.revents & POLLNVAL) == POLLNVAL) {
			printk("POLLNVAL\n");
			break;
		}

                if (nRun == 0) {
                    if (vChanged == true) {
                      nRun=1;
                      vChanged = false;
                      sendCloudMsg();
                    }
                }
                //sendCloudMsg();
	}

	printk("Disconnecting MQTT client...\n");

	err = mqtt_disconnect(&client);
	if (err) {
		printk("Could not disconnect MQTT client. Error: %d\n", err);
	}
}
```
